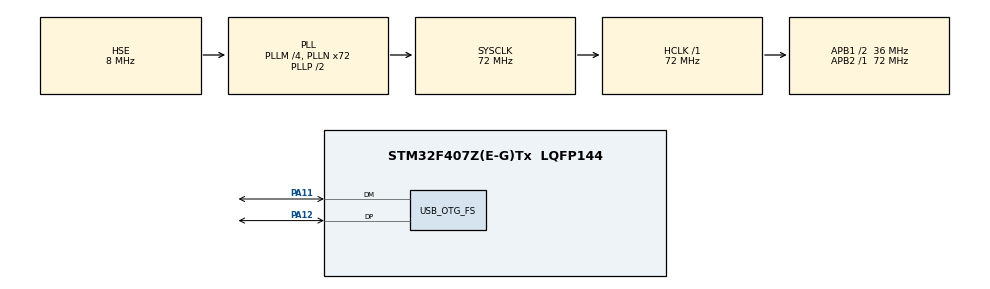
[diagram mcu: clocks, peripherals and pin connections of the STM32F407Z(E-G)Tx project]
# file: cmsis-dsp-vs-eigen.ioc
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FREERTOS.Tasks01=defaultTask,24,128,StartDefaultTask,Default,NULL,Dynamic,NULL,NULL
Mcu.Family=STM32F4
Mcu.Name=STM32F407Z(E-G)Tx
Mcu.Package=LQFP144
NVIC.OTG_FS_IRQn=true\:5\:0\:false\:false\:true\:true\:true\:true\:true
NVIC.PriorityGroup=NVIC_PRIORITYGROUP_4
NVIC.TIM1_UP_TIM10_IRQn=true\:15\:0\:false\:false\:true\:false\:false\:true\:true
NVIC.TimeBase=TIM1_UP_TIM10_IRQn
NVIC.TimeBaseIP=TIM1
PA11.Mode=Device_Only
PA11.Signal=USB_OTG_FS_DM
PA12.Mode=Device_Only
PA12.Signal=USB_OTG_FS_DP
PA13.Mode=Serial_Wire
PA13.Signal=SYS_JTMS-SWDIO
PA14.Mode=Serial_Wire
PA14.Signal=SYS_JTCK-SWCLK
PH0-OSC_IN.Mode=HSE-External-Oscillator
PH0-OSC_IN.Signal=RCC_OSC_IN
PH1-OSC_OUT.Mode=HSE-External-Oscillator
PH1-OSC_OUT.Signal=RCC_OSC_OUT
ProjectManager.HeapSize=0x200
ProjectManager.StackSize=0x400
ProjectManager.TargetToolchain=CMake
RCC.48MHZClocksFreq_Value=48000000
RCC.AHBFreq_Value=72000000
RCC.APB1CLKDivider=RCC_HCLK_DIV2
RCC.APB1Freq_Value=36000000
RCC.APB1TimFreq_Value=72000000
RCC.APB2Freq_Value=72000000
RCC.APB2TimFreq_Value=72000000
RCC.CortexFreq_Value=72000000
RCC.HCLKFreq_Value=72000000
RCC.HSE_VALUE=8000000
RCC.HSI_VALUE=16000000
RCC.LSE_VALUE=32768
RCC.PLLM=4
RCC.PLLN=72
RCC.PLLQ=3
RCC.SYSCLKFreq_VALUE=72000000
RCC.SYSCLKSource=RCC_SYSCLKSOURCE_PLLCLK
RCC.VCOOutputFreq_Value=144000000
USB_OTG_FS.VirtualMode=Device_Only
VP_FREERTOS_VS_CMSIS_V2.Mode=CMSIS_V2
VP_SYS_VS_tim1.Mode=TIM1
board=custom

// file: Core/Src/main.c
/* USER CODE BEGIN Header */
/**
  ******************************************************************************
  * @file           : main.c
  * @brief          : Main program body
  ******************************************************************************
  * @attention
  *
  * Copyright (c) 2026 STMicroelectronics.
  * All rights reserved.
  *
  * This software is licensed under terms that can be found in the LICENSE file
  * in the root directory of this software component.
  * If no LICENSE file comes with this software, it is provided AS-IS.
  *
  ******************************************************************************
  */
/* USER CODE END Header */
#include "main.h"
#include "cmsis_os.h"

/* USER CODE BEGIN Includes */
#include "app_main.h"

/* USER CODE END Includes */

PCD_HandleTypeDef hpcd_USB_OTG_FS;

/* Definitions for defaultTask */
osThreadId_t defaultTaskHandle;
const osThreadAttr_t defaultTask_attributes = {
  .name = "defaultTask",
  .stack_size = 4096 * 4,
  .priority = (osPriority_t) osPriorityNormal,
};

void SystemClock_Config(void);
static void MX_GPIO_Init(void);
static void MX_USB_OTG_FS_PCD_Init(void);
void StartDefaultTask(void *argument);

int main(void)
{

  /* MCU Configuration--------------------------------------------------------*/

  /* Reset of all peripherals, Initializes the Flash interface and the Systick. */
  HAL_Init();

  /* Configure the system clock */
  SystemClock_Config();

  /* Initialize all configured peripherals */
  MX_GPIO_Init();
  MX_USB_OTG_FS_PCD_Init();

  /* Init scheduler */
  osKernelInitialize();

  /* Create the thread(s) */
  /* creation of defaultTask */
  defaultTaskHandle = osThreadNew(StartDefaultTask, NULL, &defaultTask_attributes);

  /* Start scheduler */
  osKernelStart();

  /* We should never get here as control is now taken by the scheduler */

  /* Infinite loop */
  while (1)
  {

  }
}

void SystemClock_Config(void)
{
  RCC_OscInitTypeDef RCC_OscInitStruct = {0};
  RCC_ClkInitTypeDef RCC_ClkInitStruct = {0};

  /** Configure the main internal regulator output voltage
  */
  __HAL_RCC_PWR_CLK_ENABLE();
  __HAL_PWR_VOLTAGESCALING_CONFIG(PWR_REGULATOR_VOLTAGE_SCALE1);

  /** Initializes the RCC Oscillators according to the specified parameters
  * in the RCC_OscInitTypeDef structure.
  */
  RCC_OscInitStruct.OscillatorType = RCC_OSCILLATORTYPE_HSE;
  RCC_OscInitStruct.HSEState = RCC_HSE_ON;
  RCC_OscInitStruct.PLL.PLLState = RCC_PLL_ON;
  RCC_OscInitStruct.PLL.PLLSource = RCC_PLLSOURCE_HSE;
  RCC_OscInitStruct.PLL.PLLM = 4;
  RCC_OscInitStruct.PLL.PLLN = 72;
  RCC_OscInitStruct.PLL.PLLP = RCC_PLLP_DIV2;
  RCC_OscInitStruct.PLL.PLLQ = 3;
  if (HAL_RCC_OscConfig(&RCC_OscInitStruct) != HAL_OK)
  {
    Error_Handler();
  }

  /** Initializes the CPU, AHB and APB buses clocks
  */
  RCC_ClkInitStruct.ClockType = RCC_CLOCKTYPE_HCLK|RCC_CLOCKTYPE_SYSCLK
                              |RCC_CLOCKTYPE_PCLK1|RCC_CLOCKTYPE_PCLK2;
  RCC_ClkInitStruct.SYSCLKSource = RCC_SYSCLKSOURCE_PLLCLK;
  RCC_ClkInitStruct.AHBCLKDivider = RCC_SYSCLK_DIV1;
  RCC_ClkInitStruct.APB1CLKDivider = RCC_HCLK_DIV2;
  RCC_ClkInitStruct.APB2CLKDivider = RCC_HCLK_DIV1;

  if (HAL_RCC_ClockConfig(&RCC_ClkInitStruct, FLASH_LATENCY_2) != HAL_OK)
  {
    Error_Handler();
  }
}

static void MX_USB_OTG_FS_PCD_Init(void)
{

  hpcd_USB_OTG_FS.Instance = USB_OTG_FS;
  hpcd_USB_OTG_FS.Init.dev_endpoints = 4;
  hpcd_USB_OTG_FS.Init.speed = PCD_SPEED_FULL;
  hpcd_USB_OTG_FS.Init.dma_enable = DISABLE;
  hpcd_USB_OTG_FS.Init.phy_itface = PCD_PHY_EMBEDDED;
  hpcd_USB_OTG_FS.Init.Sof_enable = DISABLE;
  hpcd_USB_OTG_FS.Init.low_power_enable = DISABLE;
  hpcd_USB_OTG_FS.Init.lpm_enable = DISABLE;
  hpcd_USB_OTG_FS.Init.vbus_sensing_enable = DISABLE;
  hpcd_USB_OTG_FS.Init.use_dedicated_ep1 = DISABLE;
  if (HAL_PCD_Init(&hpcd_USB_OTG_FS) != HAL_OK)
  {
    Error_Handler();
  }

}

static void MX_GPIO_Init(void)
{
  GPIO_InitTypeDef GPIO_InitStruct = {0};

  /* GPIO Ports Clock Enable */
  __HAL_RCC_GPIOH_CLK_ENABLE();
  __HAL_RCC_GPIOA_CLK_ENABLE();

  /* USER CODE BEGIN MX_GPIO_Init_2 */
  /* Force a brief USB disconnect pulse on DP before USB init, then release line. */
  GPIO_InitStruct.Pin = GPIO_PIN_12;
  GPIO_InitStruct.Mode = GPIO_MODE_OUTPUT_PP;
  GPIO_InitStruct.Pull = GPIO_PULLDOWN;
  GPIO_InitStruct.Speed = GPIO_SPEED_FREQ_LOW;
  HAL_GPIO_Init(GPIOA, &GPIO_InitStruct);
  HAL_GPIO_WritePin(GPIOA, GPIO_PIN_12, GPIO_PIN_RESET);
  HAL_Delay(20);
  GPIO_InitStruct.Mode = GPIO_MODE_INPUT;
  GPIO_InitStruct.Pull = GPIO_NOPULL;
  HAL_GPIO_Init(GPIOA, &GPIO_InitStruct);
  HAL_Delay(10);

  /* USER CODE END MX_GPIO_Init_2 */
}

void StartDefaultTask(void *argument)
{
  /* USER CODE BEGIN 5 */
  UNUSED(argument);
  app_main();
  for(;;) {
    osDelay(1000);
  }
  /* USER CODE END 5 */
}

void HAL_TIM_PeriodElapsedCallback(TIM_HandleTypeDef *htim)
{
  if (htim->Instance == TIM1)
  {
    HAL_IncTick();
  }
}

void Error_Handler(void)
{
  __disable_irq();
  while (1)
  {
  }
}
